# f28003x_clk_cfg_regs register map
Vendor: Texas Instruments
Peripheral module from a debugger description file (folder C2000).
Address unit: 16 bits
Registers are 32-bit, read-write, no defined reset value unless marked. A register's access mark holds for its fields unless they carry their own. Offsets are as the file gives them; lines under a group give offsets from that group; [hi:lo] are bit positions; {n}, {i} and the like mark numbered series; 'fields as' and 'values as' point back to an identical list; <NAME> marks a mode.

## CLK_CFG_REGS — CLK CFG Registers
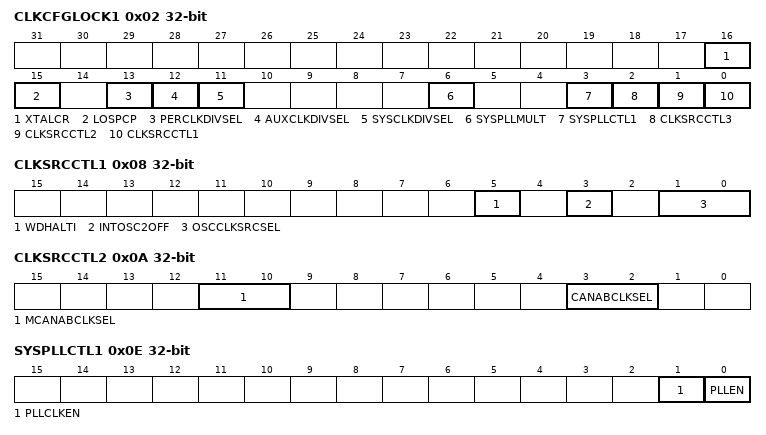
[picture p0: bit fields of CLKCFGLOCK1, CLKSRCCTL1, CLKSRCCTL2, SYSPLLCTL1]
0x02 CLKCFGLOCK1 — Lock bit for CLKCFG registers
  [16] XTALCR — Lock bit for XTALCR and XTALCR2 register
  [15] LOSPCP — Lock bit for LOSPCP register
  [13] PERCLKDIVSEL — Lock bit for PERCLKDIVSEL register
  [12] AUXCLKDIVSEL — Lock bit for AUXCLKDIVSEL register
  [11] SYSCLKDIVSEL — Lock bit for SYSCLKDIVSEL register
  [6] SYSPLLMULT — Lock bit for SYSPLLMULT register
  [3] SYSPLLCTL1 — Lock bit for SYSPLLCTL1 register
  [2] CLKSRCCTL3 — Lock bit for CLKSRCCTL3 register
  [1] CLKSRCCTL2 — Lock bit for CLKSRCCTL2 register
  [0] CLKSRCCTL1 — Lock bit for CLKSRCCTL1 register
0x08 CLKSRCCTL1 — Clock Source Control register-1
  [5] WDHALTI — Watchdog HALT Mode Ignore Bit
  [3] INTOSC2OFF — Internal Oscillator 2 Off Bit
  [1:0] OSCCLKSRCSEL — OSCCLK Source Select Bit
0x0A CLKSRCCTL2 — Clock Source Control register-2
  [11:10] MCANABCLKSEL — MCANA Bit Clock Source Select Bit
  [3:2] CANABCLKSEL — CANA Bit Clock Source Select Bit
0x0C CLKSRCCTL3 — Clock Source Control register-3
  [3:0] XCLKOUTSEL — XCLKOUT Source Select Bit
0x0E SYSPLLCTL1 — SYSPLL Control register-1
  [1] PLLCLKEN — SYSPLL bypassed or included in the PLLSYSCLK path
  [0] PLLEN — SYSPLL enable/disable bit
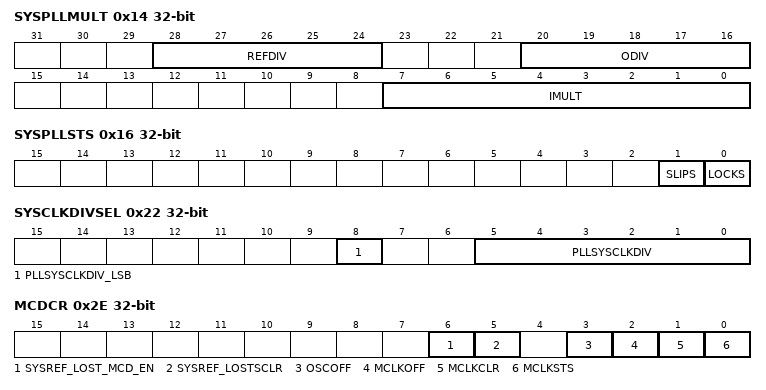
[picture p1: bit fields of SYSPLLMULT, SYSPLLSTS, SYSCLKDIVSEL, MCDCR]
0x14 SYSPLLMULT — SYSPLL Multiplier register
  [28:24] REFDIV — Reference Clock Divider
  [20:16] ODIV — Output Clock Divider
  [7:0] IMULT — SYSPLL Integer Multiplier
0x16 SYSPLLSTS ro — SYSPLL Status register
  [1] SLIPS — SYSPLL Slip Status Bit
  [0] LOCKS — SYSPLL Lock Status Bit
0x22 SYSCLKDIVSEL — System Clock Divider Select register
  [8] PLLSYSCLKDIV_LSB — This bit allows the odd division for the sys clock divider
  [5:0] PLLSYSCLKDIV — PLLSYSCLK Divide Select
0x24 AUXCLKDIVSEL — Auxillary Clock Divider Select register
  [12:8] MCANCLKDIV — Divider between CANFD Source Clock and CANFD Bit CLK
0x28 XCLKOUTDIVSEL — XCLKOUT Divider Select register
  [1:0] XCLKOUTDIV — XCLKOUT Divide Select
0x2C LOSPCP — Low Speed Clock Source Prescalar
  [2:0] LSPCLKDIV — LSPCLK Divide Select
0x2E MCDCR access per field — Missing Clock Detect Control Register
  [6] SYSREF_LOST_MCD_EN rw — Enable for PLL REF_CLK_LOST as MCD cause
  [5] SYSREF_LOSTSCLR rw — Clear for Ref clock lost status
  [3] OSCOFF rw — Oscillator Clock Off Bit
  [2] MCLKOFF rw — Missing Clock Detect Off Bit
  [1] MCLKCLR rw — Missing Clock Clear Bit
  [0] MCLKSTS ro — Missing Clock Status Bit
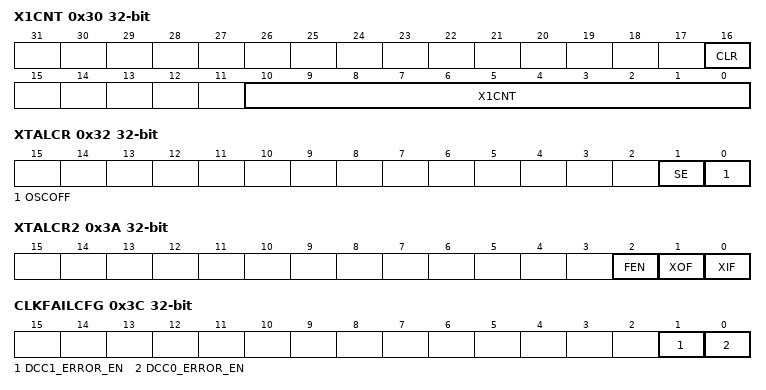
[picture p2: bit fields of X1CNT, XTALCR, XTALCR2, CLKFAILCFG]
0x30 X1CNT access per field — 10-bit Counter on X1 Clock
  [16] CLR rw — X1 Counter Clear
  [10:0] X1CNT ro — X1 Counter
0x32 XTALCR — XTAL Control Register
  [1] SE — XTAL Oscilator in Single-Ended mode
  [0] OSCOFF — XTAL Oscillator powered-down
0x3A XTALCR2 — XTAL Control Register for pad init
  [2] FEN — XOSC pads initialisation enable
  [1] XOF — XO Initial value deposited before XOSC start
  [0] XIF — XI Initial value deposited before XOSC start
0x3C CLKFAILCFG — Clock Fail cause Configuration
  [1] DCC1_ERROR_EN — DCC1 Error causes Clock fail NMI, ERROR
  [0] DCC0_ERROR_EN — DCC0 Error causes Clock fail NMI, ERROR
